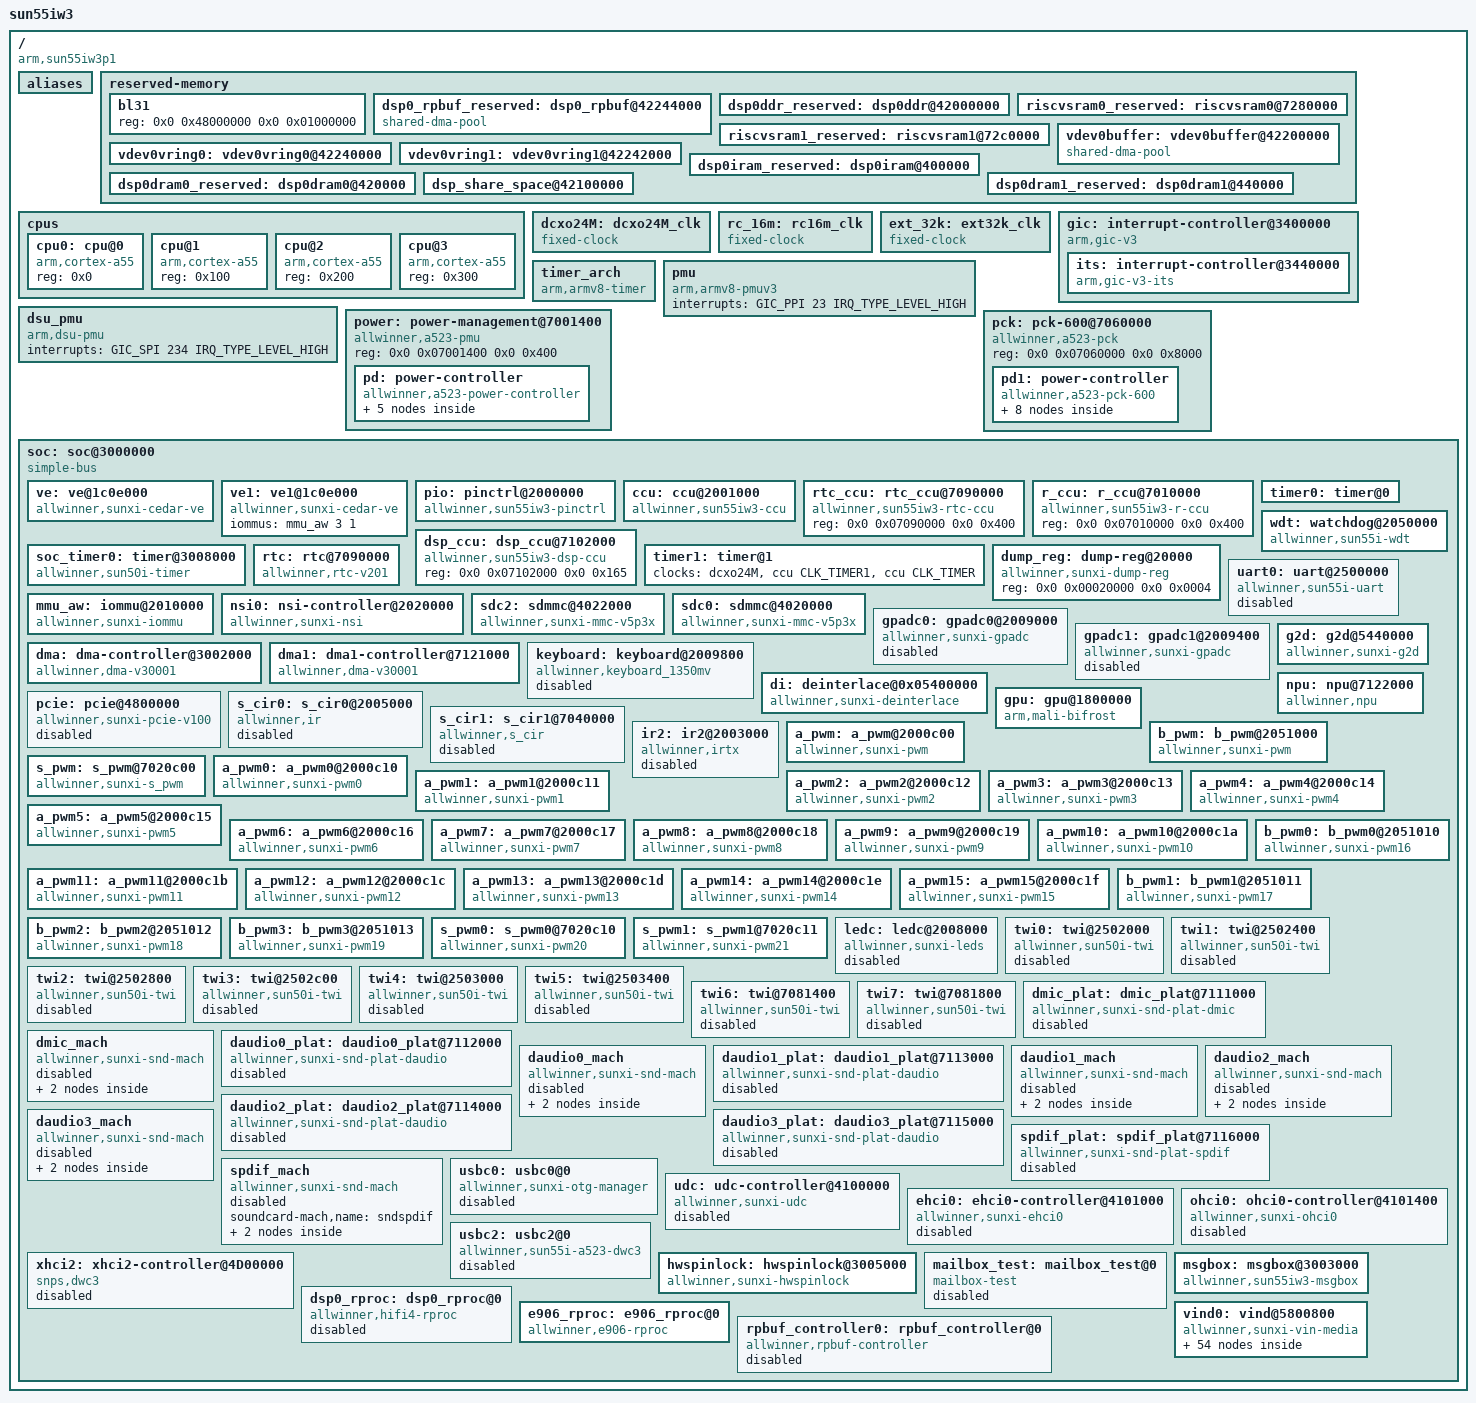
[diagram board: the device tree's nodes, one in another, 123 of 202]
// SPDX-License-Identifier: (GPL-2.0+ or MIT)
/*
 * Copyright (C) 2021 liujaun1@allwinnertech.com
 */

#include <dt-bindings/clock/sun55iw3-ccu.h>
#include <dt-bindings/clock/sun55iw3-rtc.h>
#include <dt-bindings/clock/sun55iw3-r-ccu.h>
#include <dt-bindings/clock/sun55iw3-dsp-ccu.h>
#include <dt-bindings/gpio/gpio.h>
#include <dt-bindings/interrupt-controller/arm-gic.h>
#include <dt-bindings/reset/sun55iw3-ccu.h>
#include <dt-bindings/reset/sun55iw3-r-ccu.h>
#include <dt-bindings/reset/sun55iw3-dsp-ccu.h>
#include <dt-bindings/power/a523-power.h>

/ {
	model = "sun55iw3";
	compatible = "arm,sun55iw3p1";
	interrupt-parent = <&gic>;
	#address-cells = <2>;
	#size-cells = <2>;
	aliases {
		global-timer0 = &soc_timer0;
		ir0 = &s_cir0;
		ir1 = &s_cir1;
		ir2 = &ir2;
		a-pwm = &a_pwm;
		b-pwm = &b_pwm;
		s-pwm = &s_pwm;
		a-pwm0 = &a_pwm0;
		a-pwm1 = &a_pwm1;
		a-pwm2 = &a_pwm2;
		a-pwm3 = &a_pwm3;
		a-pwm4 = &a_pwm4;
		a-pwm5 = &a_pwm5;
		a-pwm6 = &a_pwm6;
		a-pwm7 = &a_pwm7;
		a-pwm8 = &a_pwm8;
		a-pwm9 = &a_pwm9;
		a-pwm10 = &a_pwm10;
		a-pwm11 = &a_pwm11;
		a-pwm12 = &a_pwm12;
		a-pwm13 = &a_pwm13;
		a-pwm14 = &a_pwm14;
		a-pwm15 = &a_pwm15;
		b-pwm0 = &b_pwm0;
		b-pwm1 = &b_pwm1;
		b-pwm2 = &b_pwm2;
		b-pwm3 = &b_pwm3;
		s-pwm0 = &s_pwm0;
		s-pwm1 = &s_pwm1;
		pcie = &pcie;
		twi0 = &twi0;
		twi1 = &twi1;
		twi2 = &twi2;
		twi3 = &twi3;
		twi4 = &twi4;
		twi5 = &twi5;
		twi6 = &twi6;
		twi7 = &twi7;
		ve0 = &ve;
		ve1 = &ve1;
	};

	reserved-memory {
		#address-cells = <2>;
		#size-cells = <2>;
		ranges;

		bl31 {
			reg = <0x0 0x48000000 0x0 0x01000000>;
		};

		dsp0_rpbuf_reserved: dsp0_rpbuf@42244000 {
			compatible = "shared-dma-pool";
			no-map;
			reg = <0x0 0x42244000 0x0 0x2000>;
		};

		dsp0ddr_reserved: dsp0ddr@42000000 {
			reg = <0x0 0x42000000 0x0 0x00100000>;
			no-map;
		};

		riscvsram0_reserved: riscvsram0@7280000 {
			reg = <0x0 0x07280000 0x0 0x40000>;
			no-map;
		};

		riscvsram1_reserved: riscvsram1@72c0000 {
			reg = <0x0 0x072c0000 0x0 0x40000>;
			no-map;
		};

		/*
		 * The name should be "vdev%dbuffer".
		 * Its size should be not less than
		 *     RPMSG_BUF_SIZE * (num of buffers in a vring) * 2
		 *   = 512 * (num of buffers in a vring) * 2
		 */
		vdev0buffer: vdev0buffer@42200000 {
			compatible = "shared-dma-pool";
			reg = <0x0 0x42200000 0x0 0x40000>;
			no-map;
		};

		/*
		 * The name should be "vdev%dvring%d".
		 * The size of each should be not less than
		 *     PAGE_ALIGN(vring_size(num, align))
		 *   = PAGE_ALIGN(16 * num + 6 + 2 * num + (pads for align) + 6 + 8 * num)
		 *
		 * (Please refer to the vring layout in include/uapi/linux/virtio_ring.h)
		 */
		vdev0vring0: vdev0vring0@42240000 {
			reg = <0x0 0x42240000 0x0 0x2000>;
			no-map;
		};
		vdev0vring1: vdev0vring1@42242000 {
			reg = <0x0 0x42242000 0x0 0x2000>;
			no-map;
		};

		/*
		* dsp ram addr
		*/
		dsp0iram_reserved: dsp0iram@400000 {
			reg = <0x0 0x400000 0x0 0x10000>;
			no-map;
		};
		dsp0dram0_reserved: dsp0dram0@420000 {
			reg = <0x0 0x420000 0x0 0x8000>;
			no-map;
		};
		dsp0dram1_reserved: dsp0dram1@440000 {
			reg = <0x0 0x440000 0x0 0x8000>;
			no-map;
		};

		dsp_share_space@42100000 {
			no-map;
			reg = <0x0 0x42100000 0x0 0x10000>;
		};
	};

	cpus {
		#address-cells = <1>;
		#size-cells = <0>;

		cpu0: cpu@0 {
			device_type = "cpu";
			compatible = "arm,cortex-a55";
			reg = <0x0>;
		};

		cpu@1 {
			device_type = "cpu";
			compatible = "arm,cortex-a55";
			reg = <0x100>;
		};

		cpu@2 {
			device_type = "cpu";
			compatible = "arm,cortex-a55";
			reg = <0x200>;
		};

		cpu@3 {
			device_type = "cpu";
			compatible = "arm,cortex-a55";
			reg = <0x300>;
		};
	};

	dcxo24M: dcxo24M_clk {
		#clock-cells = <0>;
		compatible = "fixed-clock";
		clock-frequency = <24000000>;
		clock-output-names = "dcxo24M";
	};

	rc_16m: rc16m_clk {
		#clock-cells = <0>;
		compatible = "fixed-clock";
		clock-frequency = <16000000>;
		clock-accuracy = <300000000>;
		clock-output-names = "rc-16m";
	};

	ext_32k: ext32k_clk {
		#clock-cells = <0>;
		compatible = "fixed-clock";
		clock-frequency = <32768>;
		clock-output-names = "ext-32k";
	};

	gic: interrupt-controller@3400000 {
		compatible = "arm,gic-v3";
		#interrupt-cells = <3>;
		#address-cells = <0>;
		interrupt-controller;
		ranges;
		reg = <0x0 0x03400000 0 0x10000>, /* GIC Dist */
		      <0x0 0x03460000 0 0xFF004>; /* GIC Re */
		its: interrupt-controller@3440000 {
			compatible = "arm,gic-v3-its";
			reg = <0x0 0x03440000 0x0 0x20000>;
			msi-controller;
			#msi-cells = <1>;
		};
	};

	timer_arch {
		compatible = "arm,armv8-timer";
		interrupts = <GIC_PPI 13 (GIC_CPU_MASK_SIMPLE(4) | IRQ_TYPE_LEVEL_LOW)>,
			   <GIC_PPI 14 (GIC_CPU_MASK_SIMPLE(4) | IRQ_TYPE_LEVEL_LOW)>,
			   <GIC_PPI 11 (GIC_CPU_MASK_SIMPLE(4) | IRQ_TYPE_LEVEL_LOW)>,
			   <GIC_PPI 10 (GIC_CPU_MASK_SIMPLE(4) | IRQ_TYPE_LEVEL_LOW)>;
		clock-frequency = <24000000>;
		interrupt-parent = <&gic>;
		arm,no-tick-in-suspend;
	};

	pmu {
		compatible = "arm,armv8-pmuv3";
		interrupts = <GIC_PPI 23 IRQ_TYPE_LEVEL_HIGH>;
	};

	dsu_pmu {
		compatible = "arm,dsu-pmu";
		interrupts = <GIC_SPI 234 IRQ_TYPE_LEVEL_HIGH>;
	};

	power: power-management@7001400 {
		compatible = "allwinner,a523-pmu", "syscon", "simple-mfd";
		reg = <0x0 0x07001400 0x0 0x400>;

		pd: power-controller {
			compatible = "allwinner,a523-power-controller";
			clocks = <&r_ccu CLK_R_PPU1>;
			clock-names = "ppu";
			resets = <&r_ccu RST_R_PPU1>;
			reset-names = "ppu_rst";
			#power-domain-cells = <1>;
			#address-cells = <1>;
			#size-cells = <0>;

			pd_dsp@A523_PD_DSP {
				reg = <A523_PD_DSP>;
			};
			pd_npu@A523_PD_NPU {
				reg = <A523_PD_NPU>;
			};
			pd_audio@A523_PD_AUDIO {
				reg = <A523_PD_AUDIO>;
			};
			pd_sram@A523_PD_SRAM {
				reg = <A523_PD_SRAM>;
			};
			pd_riscv@A523_PD_RISCV {
				reg = <A523_PD_RISCV>;
			};
		};
	};

	pck: pck-600@7060000 {
		compatible = "allwinner,a523-pck", "syscon", "simple-mfd";
		reg = <0x0 0x07060000 0x0 0x8000>;

		pd1: power-controller {
			compatible = "allwinner,a523-pck-600";
			clocks = <&r_ccu CLK_R_PPU>;
			clock-names = "pck";
			resets = <&r_ccu RST_R_PPU>;
			reset-names = "pck_rst";
			#power-domain-cells = <1>;
			#address-cells = <1>;
			#size-cells = <0>;

			pd1_ve@A523_PCK_VE {
				reg = <A523_PCK_VE>;
			};
			pd1_gpu@A523_PCK_GPU {
				reg = <A523_PCK_GPU>;
			};
			pd1_vi@A523_PCK_VI {
				reg = <A523_PCK_VI>;
			};
			pd1_vo0@A523_PCK_VO0 {
				reg = <A523_PCK_VO0>;
			};
			pd1_vo1@A523_PCK_VO1 {
				reg = <A523_PCK_VO1>;
			};
			pd1_de@A523_PCK_DE {
				reg = <A523_PCK_DE>;
			};
			pd1_nand@A523_PCK_NAND {
				reg = <A523_PCK_NAND>;
			};
			pd1_pcie@A523_PCK_PCIE {
				reg = <A523_PCK_PCIE>;
			};
		};
	};

	soc: soc@3000000 {
		compatible = "simple-bus";
		#address-cells = <2>;
		#size-cells = <2>;
		ranges;

		ve: ve@1c0e000 {
			compatible = "allwinner,sunxi-cedar-ve";
			reg = <0x0 0x01c0e000 0x0 0x1000>,
				  <0x0 0x03000000 0x0 0x10>;
			interrupts = <GIC_SPI 120 IRQ_TYPE_LEVEL_HIGH>;
			clocks =<&ccu CLK_BUS_VE>, <&ccu CLK_VE>, <&ccu CLK_VE_MBUS_GATE>;
			clock-names = "bus_ve", "ve", "mbus_ve";
			resets = <&ccu RST_BUS_VE>;
			reset-names = "reset_ve";
			iommus = <&mmu_aw 3 1>;
		};

		ve1: ve1@1c0e000 {
			compatible = "allwinner,sunxi-cedar-ve";
			iommus = <&mmu_aw 3 1>;
		};

		pio: pinctrl@2000000 {
			compatible = "allwinner,sun55iw3-pinctrl";
			reg = <0x0 0x02000000 0x0 0x800>;
			interrupts = <GIC_SPI 67 IRQ_TYPE_LEVEL_HIGH>,
				     <GIC_SPI 69 IRQ_TYPE_LEVEL_HIGH>,
				     <GIC_SPI 71 IRQ_TYPE_LEVEL_HIGH>,
				     <GIC_SPI 73 IRQ_TYPE_LEVEL_HIGH>,
				     <GIC_SPI 75 IRQ_TYPE_LEVEL_HIGH>,
				     <GIC_SPI 77 IRQ_TYPE_LEVEL_HIGH>,
				     <GIC_SPI 79 IRQ_TYPE_LEVEL_HIGH>,
				     <GIC_SPI 81 IRQ_TYPE_LEVEL_HIGH>,
				     <GIC_SPI 83 IRQ_TYPE_LEVEL_HIGH>,
				     <GIC_SPI 85 IRQ_TYPE_LEVEL_HIGH>;
			clocks = <&ccu CLK_APB1>, <&dcxo24M>, <&rtc_ccu CLK_OSC32K>;
			clock-names = "apb", "hosc", "losc";
			gpio-controller;
			#gpio-cells = <3>;
			interrupt-controller;
			#interrupt-cells = <3>;

		};

		ccu: ccu@2001000 {
			compatible = "allwinner,sun55iw3-ccu";
			reg = <0x0 0x02001000 0x0 0x1000>;
			clocks = <&dcxo24M>, <&rtc_ccu CLK_OSC32K>, <&rc_16m>;
			clock-names = "hosc", "losc", "iosc";
			#clock-cells = <1>;
			#reset-cells = <1>;
		};

		rtc_ccu: rtc_ccu@7090000 {
			compatible = "allwinner,sun55iw3-rtc-ccu";
			reg = <0x0 0x07090000 0x0 0x400>;
			#clock-cells = <1>;
			#reset-cells = <1>;
		};

		r_ccu: r_ccu@7010000 {
			compatible = "allwinner,sun55iw3-r-ccu";
			reg = <0x0 0x07010000 0x0 0x400>;
			#clock-cells = <1>;
			#reset-cells = <1>;
		};

		dsp_ccu: dsp_ccu@7102000 {
			compatible = "allwinner,sun55iw3-dsp-ccu";
			reg = <0x0 0x07102000 0x0 0x165>;
			#clock-cells = <1>;
			#reset-cells = <1>;
		};

		soc_timer0: timer@3008000 {
			compatible = "allwinner,sun50i-timer";
			device_type = "soc_timer";
			reg = <0x0 0x03008000 0x0 0x400>;
			interrupt-parent = <&gic>;
			interrupts = <GIC_SPI 55 IRQ_TYPE_LEVEL_HIGH>;
			sunxi-timers = <&timer0>, <&timer1>;
		};

		timer0: timer@0 {
			clocks = <&dcxo24M>, <&ccu CLK_TIMER0>, <&ccu CLK_TIMER>;
			clock-names = "parent", "mod", "bus";
			resets = <&ccu RST_BUS_TIME>;
		};

		timer1: timer@1 {
			clocks = <&dcxo24M>, <&ccu CLK_TIMER1>, <&ccu CLK_TIMER>;
			clock-names = "parent", "mod", "bus";
		};

		dump_reg: dump-reg@20000 {
			compatible = "allwinner,sunxi-dump-reg";
			reg = <0x0 0x00020000 0x0 0x0004>;
		};

		wdt: watchdog@2050000 {
			compatible = "allwinner,sun55i-wdt";
			reg = <0x0 0x02050000 0x0 0x20>;  /* In Timers Spec */
			interrupts = <GIC_SPI 63 IRQ_TYPE_LEVEL_HIGH>;  /* In GIC Spec */
		};

		rtc: rtc@7090000 {
			compatible = "allwinner,rtc-v201";
			device_type = "rtc";
			wakeup-source;
			reg = <0x0 0x07090000 0x0 0x320>;
			interrupts = <GIC_SPI 157 IRQ_TYPE_LEVEL_HIGH>;
			clocks = <&r_ccu CLK_BUS_R_RTC>, <&rtc_ccu CLK_RTC_1K>, <&rtc_ccu CLK_RTC_SPI>;
			clock-names = "r-ahb-rtc", "rtc-1k", "rtc-spi";
			resets = <&r_ccu RST_R_RTC>;
			gpr_cur_pos = <6>;
		};

		uart0: uart@2500000 {
			compatible = "allwinner,sun55i-uart";
			reg = <0x0 0x02500000 0x0 0x400>;
			interrupts = <GIC_SPI 2 IRQ_TYPE_LEVEL_HIGH>;
			clocks = <&ccu CLK_BUS_UART0>;
			resets = <&ccu RST_BUS_UART0>;
			uart0_port = <0>;
			uart0_type = <4>;
			status = "disabled";
		};

		mmu_aw: iommu@2010000 {
			compatible = "allwinner,sunxi-iommu";
			reg = <0x0 0x02010000 0x0 0x1000>;
			interrupts = <GIC_SPI 65 IRQ_TYPE_LEVEL_HIGH>;
			interrupt-names = "iommu-irq";
			clocks = <&ccu CLK_IOMMU>;
			clock-names = "iommu";
			#iommu-cells = <2>;
		};

		nsi0:nsi-controller@2020000 {
			compatible = "allwinner,sunxi-nsi";
			interrupts = <GIC_SPI 43 IRQ_TYPE_LEVEL_HIGH>;
			reg = <0x0 0x02020000 0x0 0x10000>,
			      <0x0 0x02071000 0x0 0x400>;
			clocks = <&ccu CLK_PLL_PERI1_400M>, <&ccu CLK_MBUS>, <&ccu CLK_PLL_DDR>;
			clock-names = "pll", "bus", "sdram";
			resets = <&ccu RST_MBUS>;
			clock-frequency = <400000000>;
		};

		sdc2: sdmmc@4022000 {
			compatible = "allwinner,sunxi-mmc-v5p3x";
			device_type = "sdc2";
			reg = <0x0 0x04022000 0x0 0x1000>;
			interrupts = <GIC_SPI 42 IRQ_TYPE_LEVEL_HIGH>;
			clocks = <&dcxo24M>,
			<&ccu CLK_SMHC2>,
			<&ccu CLK_BUS_SMHC2>;
			clock-names = "osc24m","mmc","ahb";
			resets = <&ccu RST_BUS_SMHC2>;
			reset-names = "rst";
			bus-width = <8>;
			req-page-count = <2>;
			cap-mmc-highspeed;
			cap-cmd23;
			mmc-cache-ctrl;
			non-removable;
			/*max-frequency = <200000000>;*/
			max-frequency = <50000000>;
			cap-erase;
			mmc-high-capacity-erase-size;
			no-sdio;
			no-sd;
			/*-- speed mode --*/
			/*sm0: DS26_SDR12*/
			/*sm1: HSSDR52_SDR25*/
			/*sm2: HSDDR52_DDR50*/
			/*sm3: HS200_SDR104*/
			/*sm4: HS400*/
			/*-- frequency point --*/
			/*f0: CLK_400K*/
			/*f1: CLK_25M*/
			/*f2: CLK_50M*/
			/*f3: CLK_100M*/
			/*f4: CLK_150M*/
			/*f5: CLK_200M*/

			sdc_tm4_sm0_freq0 = <0>;
			sdc_tm4_sm0_freq1 = <0>;
			sdc_tm4_sm1_freq0 = <0x00000000>;
			sdc_tm4_sm1_freq1 = <0>;
			sdc_tm4_sm2_freq0 = <0x00000000>;
			sdc_tm4_sm2_freq1 = <0>;
			sdc_tm4_sm3_freq0 = <0x05000000>;
			sdc_tm4_sm3_freq1 = <0x00000005>;
			sdc_tm4_sm4_freq0 = <0x00050000>;
			sdc_tm4_sm4_freq1 = <0x00000004>;
			sdc_tm4_sm4_freq0_cmd = <0>;
			sdc_tm4_sm4_freq1_cmd = <0>;

			/*vmmc-supply = <&reg_3p3v>;*/
			/*vqmc-supply = <&reg_3p3v>;*/
			/*vdmc-supply = <&reg_3p3v>;*/
			/*vmmc = "vcc-card";*/
			/*vqmc = "";*/
			/*vdmc = "";*/
			/*sunxi-power-save-mode;*/
		};

		sdc0: sdmmc@4020000 {
			compatible = "allwinner,sunxi-mmc-v5p3x";
			device_type = "sdc0";
			reg = <0x0 0x04020000 0x0 0x1000>;
			interrupts = <GIC_SPI 40 IRQ_TYPE_LEVEL_HIGH>;
			clocks = <&dcxo24M>,
				<&ccu CLK_SMHC0>,
				<&ccu CLK_BUS_SMHC0>;
			clock-names = "osc24m","mmc","ahb";
			resets = <&ccu RST_BUS_SMHC0>;
			reset-names = "rst";
		};

		gpadc0: gpadc0@2009000 {
			compatible = "allwinner,sunxi-gpadc";
			reg = <0x0 0x02009000 0x0 0x200>;
			interrupts = <GIC_SPI 61 IRQ_TYPE_LEVEL_HIGH>;
			clocks = <&ccu CLK_BUS_GPADC0>;
			clock-names = "bus";
			resets = <&ccu RST_BUS_GPADC0>;
			status = "disabled";
		};

		gpadc1: gpadc1@2009400 {
			compatible = "allwinner,sunxi-gpadc";
			reg = <0x0 0x02009400 0x0 0x200>;
			interrupts = <GIC_SPI 64 IRQ_TYPE_LEVEL_HIGH>;
			clocks = <&ccu CLK_BUS_GPADC1>;
			clock-names = "bus";
			resets = <&ccu RST_BUS_GPADC1>;
			status = "disabled";
		};

		dma:dma-controller@3002000 {
			compatible = "allwinner,dma-v30001";
			reg = <0x0 0x03002000 0x0 0x1000>;
			interrupts = <GIC_SPI 50 IRQ_TYPE_LEVEL_HIGH>;
			clocks = <&ccu CLK_DMA>, <&ccu CLK_DMA_MBUS_GATE>;
			clock-names = "bus", "mbus";
			dma-channels = <16>;
			dma-requests = <54>;
			resets = <&ccu RST_BUS_DMA>;
			#dma-cells = <1>;
		};

		dma1:dma1-controller@7121000 {
			compatible = "allwinner,dma-v30001";
			reg = <0x0 0x07121000 0x0 0x1000>;
			interrupts = <GIC_SPI 197 IRQ_TYPE_LEVEL_HIGH>;
			clocks = <&dsp_ccu CLK_BUS_DSP_DMA>, <&dsp_ccu CLK_BUS_DSP_MBUS>;
			clock-names = "bus", "mbus";
			dma-channels = <16>;
			dma-requests = <54>;
			resets = <&dsp_ccu RST_BUS_DSP_DMA>;
			#dma-cells = <1>;
		};

		keyboard: keyboard@2009800 {
			compatible = "allwinner,keyboard_1350mv";
			reg = <0x0 0x02009800 0x0 0x100>;
			interrupts = <GIC_SPI 66 IRQ_TYPE_NONE>;
			clocks = <&ccu CLK_LRADC>;
			resets = <&ccu RST_BUS_LRADC>;
			status = "disabled";
			key_cnt = <5>;
			key0 = <212 115>;
			key1 = <409 114>;
			key2 = <473 139>;
			key3 = <525 28>;
			key4 = <527 172>;
		};

		di:deinterlace@0x05400000{
			#address-cells = <1>;
			#size-cells = <0>;
			compatible = "allwinner,sunxi-deinterlace";
			reg = <0x0 0x05400000 0x0 0x040000>;
			interrupts = <GIC_SPI 88 IRQ_TYPE_LEVEL_HIGH>;
			iommus = <&mmu_aw 6 1>;
			status = "okay";

			clocks = <&ccu CLK_DI>,
				 <&ccu CLK_BUS_DI>,
				 <&ccu CLK_PLL_PERI0_2X>;
			clock-names = "clk_di",
				      "clk_bus_di",
				      "pll_periph";
			resets = <&ccu RST_BUS_DI>;
			reset-names = "rst_bus_di";

			assigned-clocks = <&ccu CLK_DI>;
			assigned-clock-parents = <&ccu CLK_PLL_PERI0_2X>;
			assigned-clock-rates = <300000000>;
		};

		g2d: g2d@5440000 {
			compatible = "allwinner,sunxi-g2d";
			reg = <0x0 0x05440000 0x0 0x3ffff>;
			interrupts = <GIC_SPI 143 IRQ_TYPE_LEVEL_HIGH>;
			clocks = <&ccu CLK_BUS_G2D>, <&ccu CLK_G2D>;
			clock-names = "bus", "g2d";
			resets = <&ccu RST_BUS_G2D>;
			assigned-clocks = <&ccu CLK_G2D>;
			assigned-clock-parents = <&ccu CLK_PLL_VIDEO1_4X>;
			/*assigned-clock-rates = <300000000>;*/
			iommus = <&mmu_aw 4 1>;
		};

		npu: npu@7122000 {
			compatible = "allwinner,npu";
			reg = <0x0 0x07122000 0x0 0x1000>;
			device_type = "npu";
			dev_name = "npu";
			interrupts = <GIC_SPI 199 IRQ_TYPE_LEVEL_HIGH>;
			clocks = <&ccu CLK_NPU>, <&ccu CLK_PLL_NPU_2X>;
			clock-names = "clk_npu", "clk_parent";
			clock-frequency = <600000000>;
			resets = <&dsp_ccu RST_BUS_DSP_NPU>;
			interrupt-names = "npu";
			etatus = "okay";
/*
			power-domains = <&pd A523_PD_NPU>;
*/
			};

		gpu: gpu@1800000 {
			device_type = "gpu";
			compatible = "arm,mali-bifrost";
			reg = <0x0 0x01800000 0x0 0x40000>;
			interrupts = <GIC_SPI 117 IRQ_TYPE_LEVEL_HIGH>,
				     <GIC_SPI 118 IRQ_TYPE_LEVEL_HIGH>,
				     <GIC_SPI 119 IRQ_TYPE_LEVEL_HIGH>;
			interrupt-names = "JOB", "MMU", "GPU";
			clocks = <&ccu CLK_PLL_GPU>, <&ccu CLK_GPU>;
			clock-names = "clk_parent", "clk_mali";

			resets = <&ccu RST_BUS_GPU>;
			reset-names = "rst_bus_gpu";
			power-domains = <&pd1 A523_PCK_GPU>;
			/*#cooling-cells = <2>;
			ipa_dvfs:ipa_dvfs {
				compatible = "arm,mali-simple-power-model";
				static-coefficient = <17000>;
				dynamic-coefficient = <750>;
				ts = <254682 9576 0xffffff98 4>;
				thermal-zone = "gpu-thermal-zone";
				ss-coefficient = <36>;
				ff-coefficient = <291>;
			};*/
		};

		pcie: pcie@4800000 {
			#address-cells = <3>;
			#size-cells = <2>;
			compatible = "allwinner,sunxi-pcie-v100";
			bus-range = <0x0 0xff>;
			reg = <0 0x04800000 0 0x480000>,
			      <0 0x04f00000 0 0x88>,
			      <0 0x02001a84 0 0x30>;
			reg-names = "dbi", "pcie-phy", "clk_add";
			device_type = "pci";
			ranges = <0x00000800 0 0x20000000 0x0 0x20000000 0 0x01000000
				  0x81000000 0 0x21000000 0x0 0x21000000 0 0x01000000
				  0x82000000 0 0x22000000 0x0 0x22000000 0 0x07000000>;
			num-lanes = <1>;
			interrupts = <GIC_SPI 107 IRQ_TYPE_LEVEL_HIGH>,
				     <GIC_SPI 106 IRQ_TYPE_LEVEL_HIGH>,
				     <GIC_SPI 98  IRQ_TYPE_LEVEL_HIGH>,
				     <GIC_SPI 99  IRQ_TYPE_LEVEL_HIGH>,
				     <GIC_SPI 100 IRQ_TYPE_LEVEL_HIGH>,
				     <GIC_SPI 101 IRQ_TYPE_LEVEL_HIGH>,
				     <GIC_SPI 102 IRQ_TYPE_LEVEL_HIGH>,
				     <GIC_SPI 103 IRQ_TYPE_LEVEL_HIGH>,
				     <GIC_SPI 104 IRQ_TYPE_LEVEL_HIGH>,
				     <GIC_SPI 105 IRQ_TYPE_LEVEL_HIGH>;
			interrupt-names = "msi", "sii", "edma-w0", "edma-w1", "edma-w2", "edma-w3",
					  "edma-r0", "edma-r1", "edma-r2", "edma-r3";
			#interrupt-cells = <1>;
			num-edma = <4>;
			pcie_speed_gen = <1>;
			num-ib-windows = <8>;
			num-ob-windows = <8>;
			clocks = <&ccu CLK_USB3_REF >, <&ccu CLK_PLL_PERI0_200M>, <&ccu CLK_PCIE_AUX>;
			clock-names = "pclk_ref", "pclk_per", "pclk_aux";
			resets = <&ccu RST_BUS_PCIE_USB3>;
			reset-names = "pclk_rst";
			busno = <0>;
			/* msi-map = <0x0 &its 0x0 0x1000>; Do not use ITS: Need to modify the ITS driver */
			status = "disabled";
		};

		s_cir0: s_cir0@2005000 {
			compatible = "allwinner,ir";
			reg = <0x0 0x02005000 0x0 0x400>;
			interrupts = <GIC_SPI 27 IRQ_TYPE_LEVEL_HIGH>;
			clocks = <&ccu CLK_BUS_IRRX>, <&dcxo24M>, <&ccu CLK_IRRX>;
			clock-names = "bus", "pclk", "mclk";
			resets = <&ccu RST_BUS_IRRX>;
			status = "disabled";
		};

		s_cir1: s_cir1@7040000 {
			compatible = "allwinner,s_cir";
			reg = <0x0 0x07040000 0x0 0x400>;
			interrupts = <GIC_SPI 167 IRQ_TYPE_LEVEL_HIGH>;
			clocks = <&r_ccu CLK_BUS_R_IRRX>, <&dcxo24M>, <&r_ccu CLK_R_IRRX>;
			clock-names = "bus", "pclk", "mclk";
			resets = <&r_ccu RST_R_IRRX>;
			status = "disabled";
		};

		ir2: ir2@2003000 {
			compatible = "allwinner,irtx";
			reg = <0x0 0x02003000 0x0 0x400>;
			interrupts = <GIC_SPI 26 IRQ_TYPE_LEVEL_HIGH>;
			clocks = <&ccu CLK_BUS_IRTX>, <&dcxo24M>, <&ccu CLK_IRTX>;
			clock-names = "bus", "pclk", "mclk";
			resets = <&ccu RST_BUS_IRTX>;
			status = "disabled";
		};

		a_pwm: a_pwm@2000c00 {
			#pwm-cells = <0x3>;
			compatible = "allwinner,sunxi-pwm";
			reg = <0x0 0x02000c00 0x0 0x3ff>;
			clocks = <&ccu CLK_PWM>;
			resets = <&ccu RST_BUS_PWM>;
			pwm-number = <16>;
			pwm-base = <0x0>;
			sunxi-pwms = <&a_pwm0>, <&a_pwm1>, <&a_pwm2>, <&a_pwm3>, <&a_pwm4>,
				<&a_pwm5>, <&a_pwm6>, <&a_pwm7>, <&a_pwm8>, <&a_pwm9>,
				<&a_pwm10>, <&a_pwm11>, <&a_pwm12>, <&a_pwm13>,
				<&a_pwm14>, <&a_pwm15>;
		};

		b_pwm: b_pwm@2051000 {
			#pwm-cells = <0x3>;
			compatible = "allwinner,sunxi-pwm";
			reg = <0x0 0x02051000 0x0 0x3ff>;
			clocks = <&ccu CLK_PWM1>;
			resets = <&ccu RST_BUS_PWM1>;
			pwm-number = <4>;
			pwm-base = <0x10>;
			sunxi-pwms = <&b_pwm0>, <&b_pwm1>, <&b_pwm2>, <&b_pwm3>;
		};

		s_pwm: s_pwm@7020c00 {
			#pwm-cells = <0x3>;
			compatible = "allwinner,sunxi-s_pwm";
			reg = <0x0 0x07020c00 0x0 0x3ff>;
			clocks = <&r_ccu CLK_R_PWM>;
			resets = <&r_ccu RST_R_PWM>;
			pwm-number = <2>;
			pwm-base = <0x20>;
			sunxi-pwms = <&s_pwm0>, <&s_pwm1>;
		};

		a_pwm0: a_pwm0@2000c10 {
			compatible = "allwinner,sunxi-pwm0";
			pinctrl-names = "active", "sleep";
			reg = <0x0 0x02000c10 0x0 0x4>;
			reg_base = <0x02000c00>;
		};

		a_pwm1: a_pwm1@2000c11 {
			compatible = "allwinner,sunxi-pwm1";
			pinctrl-names = "active", "sleep";
			reg = <0x0 0x02000c11 0x0 0x4>;
			reg_base = <0x02000c00>;
		};

		a_pwm2: a_pwm2@2000c12 {
			compatible = "allwinner,sunxi-pwm2";
			pinctrl-names = "active", "sleep";
			reg = <0x0 0x02000c12 0x0 0x4>;
			reg_base = <0x02000c00>;
		};

		a_pwm3: a_pwm3@2000c13 {
			compatible = "allwinner,sunxi-pwm3";
			pinctrl-names = "active", "sleep";
			reg = <0x0 0x02000c13 0x0 0x4>;
			reg_base = <0x02000c00>;
		};

		a_pwm4: a_pwm4@2000c14 {
			compatible = "allwinner,sunxi-pwm4";
			pinctrl-names = "active", "sleep";
			reg = <0x0 0x02000c14 0x0 0x4>;
			reg_base = <0x02000c00>;
		};

		a_pwm5: a_pwm5@2000c15 {
			compatible = "allwinner,sunxi-pwm5";
			pinctrl-names = "active", "sleep";
			reg = <0x0 0x02000c15 0x0 0x4>;
			reg_base = <0x02000c00>;
		};

		a_pwm6: a_pwm6@2000c16 {
			compatible = "allwinner,sunxi-pwm6";
			pinctrl-names = "active", "sleep";
			reg = <0x0 0x02000c16 0x0 0x4>;
			reg_base = <0x02000c00>;
		};

		a_pwm7: a_pwm7@2000c17 {
			compatible = "allwinner,sunxi-pwm7";
			pinctrl-names = "active", "sleep";
			reg = <0x0 0x02000c17 0x0 0x4>;
			reg_base = <0x02000c00>;
		};

		a_pwm8: a_pwm8@2000c18 {
			compatible = "allwinner,sunxi-pwm8";
			pinctrl-names = "active", "sleep";
			reg = <0x0 0x02000c18 0x0 0x4>;
			reg_base = <0x02000c00>;
		};

		a_pwm9: a_pwm9@2000c19 {
			compatible = "allwinner,sunxi-pwm9";
			pinctrl-names = "active", "sleep";
			reg = <0x0 0x02000c19 0x0 0x4>;
			reg_base = <0x02000c00>;
		};

		a_pwm10: a_pwm10@2000c1a {
			compatible = "allwinner,sunxi-pwm10";
			pinctrl-names = "active", "sleep";
			reg = <0x0 0x02000c1a 0x0 0x4>;
			reg_base = <0x02000c00>;
		};

		a_pwm11: a_pwm11@2000c1b {
			compatible = "allwinner,sunxi-pwm11";
			pinctrl-names = "active", "sleep";
			reg = <0x0 0x02000c1b 0x0 0x4>;
			reg_base = <0x02000c00>;
		};

		a_pwm12: a_pwm12@2000c1c {
			compatible = "allwinner,sunxi-pwm12";
			pinctrl-names = "active", "sleep";
			reg = <0x0 0x02000c1c 0x0 0x4>;
			reg_base = <0x02000c00>;
		};

		a_pwm13: a_pwm13@2000c1d {
			compatible = "allwinner,sunxi-pwm13";
			pinctrl-names = "active", "sleep";
			reg = <0x0 0x02000c1d 0x0 0x4>;
			reg_base = <0x02000c00>;
		};

		a_pwm14: a_pwm14@2000c1e {
			compatible = "allwinner,sunxi-pwm14";
			pinctrl-names = "active", "sleep";
			reg = <0x0 0x02000c1e 0x0 0x4>;
			reg_base = <0x02000c00>;
		};

		a_pwm15: a_pwm15@2000c1f {
			compatible = "allwinner,sunxi-pwm15";
			pinctrl-names = "active", "sleep";
			reg = <0x0 0x02000c1f 0x0 0x4>;
			reg_base = <0x02000c00>;
		};

		b_pwm0: b_pwm0@2051010 {
			compatible = "allwinner,sunxi-pwm16";
			pinctrl-names = "active", "sleep";
			reg = <0x0 0x02051010 0x0 0x4>;
			reg_base = <0x02051000>;
		};

		b_pwm1: b_pwm1@2051011 {
			compatible = "allwinner,sunxi-pwm17";
			pinctrl-names = "active", "sleep";
			reg = <0x0 0x02051011 0x0 0x4>;
			reg_base = <0x02051000>;
		};

		b_pwm2: b_pwm2@2051012 {
			compatible = "allwinner,sunxi-pwm18";
			pinctrl-names = "active", "sleep";
			reg = <0x0 0x02051012 0x0 0x4>;
			reg_base = <0x02051000>;
		};

		b_pwm3: b_pwm3@2051013 {
			compatible = "allwinner,sunxi-pwm19";
			pinctrl-names = "active", "sleep";
			reg = <0x0 0x02051013 0x0 0x4>;
			reg_base = <0x02051000>;
		};

		s_pwm0: s_pwm0@7020c10 {
			compatible = "allwinner,sunxi-pwm20";
			pinctrl-names = "active", "sleep";
			reg = <0x0 0x07020c10 0x0 0x4>;
			reg_base = <0x07020c00>;
		};

		s_pwm1: s_pwm1@7020c11 {
			compatible = "allwinner,sunxi-pwm21";
			pinctrl-names = "active", "sleep";
			reg = <0x0 0x07020c11 0x0 0x4>;
			reg_base = <0x07020c00>;
		};

		ledc: ledc@2008000 {
			#address-cells = <1>;
			#size-cells = <0>;
			compatible = "allwinner,sunxi-leds";
			reg = <0x0 0x02008000 0x0 0x400>;
			interrupts = <GIC_SPI 28 IRQ_TYPE_LEVEL_HIGH>;
			clocks = <&ccu CLK_LEDC>, <&ccu CLK_BUS_LEDC>;
			clock-names = "clk_ledc", "clk_cpuapb";
			resets = <&ccu RST_BUS_LEDC>;
			reset-names = "ledc_reset";
			dmas = <&dma 42>, <&dma 42>;
			dma-names = "rx", "tx";
			status = "disabled";
		};

		twi0: twi@2502000 {
			#address-cells = <1>;
			#size-cells = <0>;
			compatible = "allwinner,sun50i-twi";
			device_type = "twi0";
			reg = <0x0 0x02502000 0x0 0x400>;
			interrupts = <GIC_SPI 10 IRQ_TYPE_LEVEL_HIGH>;
			clocks = <&ccu CLK_TWI0>;
			clock-names = "bus";
			resets = <&ccu RST_BUS_TWI0>;
			dmas = <&dma 43>, <&dma 43>;
			dma-names = "tx", "rx";
			status = "disabled";
		};

		twi1: twi@2502400 {
			#address-cells = <1>;
			#size-cells = <0>;
			compatible = "allwinner,sun50i-twi";
			device_type = "twi1";
			reg = <0x0 0x02502400 0x0 0x400>;
			interrupts = <GIC_SPI 11 IRQ_TYPE_LEVEL_HIGH>;
			clocks = <&ccu CLK_TWI1>;
			clock-names = "bus";
			resets = <&ccu RST_BUS_TWI1>;
			dmas = <&dma 44>, <&dma 44>;
			dma-names = "tx", "rx";
			status = "disabled";
		};

		twi2: twi@2502800 {
			#address-cells = <1>;
			#size-cells = <0>;
			compatible = "allwinner,sun50i-twi";
			device_type = "twi2";
			reg = <0x0 0x02502800 0x0 0x400>;
			interrupts = <GIC_SPI 12 IRQ_TYPE_LEVEL_HIGH>;
			clocks = <&ccu CLK_TWI2>;
			clock-names = "bus";
			resets = <&ccu RST_BUS_TWI2>;
			dmas = <&dma 45>, <&dma 45>;
			dma-names = "tx", "rx";
			status = "disabled";
		};

		twi3: twi@2502c00 {
			#address-cells = <1>;
			#size-cells = <0>;
			compatible = "allwinner,sun50i-twi";
			device_type = "twi3";
			reg = <0x0 0x02502c00 0x0 0x400>;
			interrupts = <GIC_SPI 13 IRQ_TYPE_LEVEL_HIGH>;
			clocks = <&ccu CLK_TWI3>;
			clock-names = "bus";
			resets = <&ccu RST_BUS_TWI3>;
			dmas = <&dma 46>, <&dma 46>;
			dma-names = "tx", "rx";
			status = "disabled";
		};

		twi4: twi@2503000 {
			#address-cells = <1>;
			#size-cells = <0>;
			compatible = "allwinner,sun50i-twi";
			device_type = "twi4";
			reg = <0x0 0x02503000 0x0 0x400>;
			interrupts = <GIC_SPI 14 IRQ_TYPE_LEVEL_HIGH>;
			clocks = <&ccu CLK_TWI4>;
			clock-names = "bus";
			resets = <&ccu RST_BUS_TWI4>;
			dmas = <&dma 47>, <&dma 47>;
			dma-names = "tx", "rx";
			status = "disabled";
		};

		twi5: twi@2503400{
			#address-cells = <1>;
			#size-cells = <0>;
			compatible = "allwinner,sun50i-twi";
			device_type = "twi5";
			reg = <0x0 0x02503400 0x0 0x400>;
			interrupts = <GIC_SPI 15 IRQ_TYPE_LEVEL_HIGH>;
			clocks = <&ccu CLK_TWI5>;
			clock-names = "bus";
			resets = <&ccu RST_BUS_TWI5>;
			dmas = <&dma 48>, <&dma 48>;
			dma-names = "tx", "rx";
			status = "disabled";
		};

		twi6: twi@7081400 {
			#address-cells = <1>;
			#size-cells = <0>;
			compatible = "allwinner,sun50i-twi";
			device_type = "twi6";
			reg = <0x0 0x07081400 0x0 0x400>;
			interrupts = <GIC_SPI 164 IRQ_TYPE_LEVEL_HIGH>;
			clocks = <&r_ccu CLK_BUS_R_TWI0>;
			clock-names = "bus";
			resets = <&r_ccu RST_R_TWI0>;
			dmas = <&dma 49>, <&dma 49>;
			dma-names = "tx", "rx";
			status = "disabled";
		};

		twi7: twi@7081800 {
			#address-cells = <1>;
			#size-cells = <0>;
			compatible = "allwinner,sun50i-twi";
			device_type = "twi7";
			reg = <0x0 0x07081800 0x0 0x400>;
			interrupts = <GIC_SPI 165 IRQ_TYPE_LEVEL_HIGH>;
			clocks = <&r_ccu CLK_BUS_R_TWI1>;
			clock-names = "bus";
			resets = <&r_ccu RST_R_TWI1>;
			dmas = <&dma 50>, <&dma 50>;
			dma-names = "tx", "rx";
			status = "disabled";
		};

		/* audio dirver module -> dmic */
		dmic_plat:dmic_plat@7111000 {
			#sound-dai-cells = <0>;
			compatible	= "allwinner,sunxi-snd-plat-dmic";
			reg		= <0x0 0x07111000 0x0 0x50>;
			resets		= <&dsp_ccu RST_BUS_DSP_DMIC>;
			clocks		= <&dsp_ccu CLK_BUS_DSP_DMIC>,
					  <&dsp_ccu CLK_PLL_DSP_AUDIO1_DIV2>,
					  <&dsp_ccu CLK_PLL_DSP_AUDIO1_DIV5>,
					  <&ccu CLK_PLL_AUDIO0_4X>,
					  <&dsp_ccu CLK_DSP_DMIC>;
			clock-names	= "clk_bus_dmic",
					  "clk_pll_audio1_d2",
					  "clk_pll_audio1_d5",
					  "clk_pll_audio0_4x",
					  "clk_dmic";
			dmas		= <&dma1 8>;
			dma-names	= "rx";
			capture-cma	= <128>;
			rx-fifo-size	= <128>;
			status = "disabled";
		};

		dmic_mach:dmic_mach{
			compatible = "allwinner,sunxi-snd-mach";
			soundcard-mach,name		= "snddmic";
			soundcard-mach,capture-only;
			status = "disabled";
			soundcard-mach,cpu {
				sound-dai = <&dmic_plat>;
			};
			soundcard-mach,codec {
			};
		};

		/* audio dirver module -> I2S/PCM */
		daudio0_plat:daudio0_plat@7112000 {
			#sound-dai-cells = <0>;
			compatible = "allwinner,sunxi-snd-plat-daudio";
			reg		= <0x0 0x07112000 0x0 0xA0>;
			resets		= <&dsp_ccu RST_BUS_DSP_I2S0>;
			clocks		= <&dsp_ccu CLK_BUS_DSP_I2S0>,
					  <&dsp_ccu CLK_PLL_DSP_AUDIO1_DIV2>,
					  <&dsp_ccu CLK_PLL_DSP_AUDIO1_DIV5>,
					  <&ccu CLK_PLL_AUDIO0_4X>,
					  <&dsp_ccu CLK_DSP_I2S0>;
			clock-names	= "clk_bus_i2s",
					  "clk_pll_audio1_d2",
					  "clk_pll_audio1_d5",
					  "clk_pll_audio0_4x",
					  "clk_i2s";
			dmas		= <&dma1 3>, <&dma1 3>;
			dma-names	= "tx", "rx";
			playback-cma	= <128>;
			capture-cma	= <128>;
			tx-fifo-size	= <128>;
			rx-fifo-size	= <128>;
			status = "disabled";
		};

		daudio0_mach:daudio0_mach{
			compatible = "allwinner,sunxi-snd-mach";
			soundcard-mach,name		= "snddaudio0";
			soundcard-mach,format		= "i2s";
			soundcard-mach,slot-num		= <2>;
			soundcard-mach,slot-width	= <32>;
			status = "disabled";
			soundcard-mach,cpu {
				sound-dai = <&daudio0_plat>;
			};
			soundcard-mach,codec {
			};
		};

		daudio1_plat:daudio1_plat@7113000 {
			#sound-dai-cells = <0>;
			compatible = "allwinner,sunxi-snd-plat-daudio";
			reg		= <0x0 0x07113000 0x0 0xA0>;
			resets		= <&dsp_ccu RST_BUS_DSP_I2S1>;
			clocks		= <&dsp_ccu CLK_BUS_DSP_I2S1>,
					  <&dsp_ccu CLK_PLL_DSP_AUDIO1_DIV2>,
					  <&dsp_ccu CLK_PLL_DSP_AUDIO1_DIV5>,
					  <&ccu CLK_PLL_AUDIO0_4X>,
					  <&dsp_ccu CLK_DSP_I2S1>;
			clock-names	= "clk_bus_i2s",
					  "clk_pll_audio1_d2",
					  "clk_pll_audio1_d5",
					  "clk_pll_audio0_4x",
					  "clk_i2s";
			dmas		= <&dma1 4>, <&dma1 4>;
			dma-names	= "tx", "rx";
			playback-cma	= <128>;
			capture-cma	= <128>;
			tx-fifo-size	= <128>;
			rx-fifo-size	= <128>;
			status = "disabled";
		};

		daudio1_mach:daudio1_mach{
			compatible = "allwinner,sunxi-snd-mach";
			soundcard-mach,name		= "snddaudio1";
			soundcard-mach,format		= "i2s";
			soundcard-mach,slot-num		= <2>;
			soundcard-mach,slot-width	= <32>;
			status = "disabled";
			soundcard-mach,cpu {
				sound-dai = <&daudio1_plat>;
			};
			soundcard-mach,codec {
			};
		};

		daudio2_plat:daudio2_plat@7114000 {
			#sound-dai-cells = <0>;
			compatible = "allwinner,sunxi-snd-plat-daudio";
			reg		= <0x0 0x07114000 0x0 0xA0>;
			resets		= <&dsp_ccu RST_BUS_DSP_I2S2>;
			clocks		= <&dsp_ccu CLK_BUS_DSP_I2S2>,
					  <&dsp_ccu CLK_PLL_DSP_AUDIO1_DIV2>,
					  <&dsp_ccu CLK_PLL_DSP_AUDIO1_DIV5>,
					  <&ccu CLK_PLL_AUDIO0_4X>,
					  <&dsp_ccu CLK_DSP_I2S2>;
			clock-names	= "clk_bus_i2s",
					  "clk_pll_audio1_d2",
					  "clk_pll_audio1_d5",
					  "clk_pll_audio0_4x",
					  "clk_i2s";
			dmas		= <&dma1 5>, <&dma1 5>;
			dma-names	= "tx", "rx";
			playback-cma	= <128>;
			capture-cma	= <128>;
			tx-fifo-size	= <128>;
			rx-fifo-size	= <128>;
			status = "disabled";
		};

		daudio2_mach:daudio2_mach{
			compatible = "allwinner,sunxi-snd-mach";
			soundcard-mach,name		= "snddaudio2";
			soundcard-mach,format		= "i2s";
			soundcard-mach,slot-num		= <2>;
			soundcard-mach,slot-width	= <32>;
			status = "disabled";
			soundcard-mach,cpu {
				sound-dai = <&daudio2_plat>;
			};
			soundcard-mach,codec {
			};
		};

		daudio3_plat:daudio3_plat@7115000 {
			#sound-dai-cells = <0>;
			compatible = "allwinner,sunxi-snd-plat-daudio";
			reg		= <0x0 0x07115000 0x0 0xA0>;
			resets		= <&dsp_ccu RST_BUS_DSP_I2S3>;
			clocks		= <&dsp_ccu CLK_BUS_DSP_I2S3>,
					  <&dsp_ccu CLK_PLL_DSP_AUDIO1_DIV2>,
					  <&dsp_ccu CLK_PLL_DSP_AUDIO1_DIV5>,
					  <&ccu CLK_PLL_AUDIO0_4X>,
					  <&ccu CLK_PLL_PERI1_600M>,
					  <&dsp_ccu CLK_DSP_I2S3_ASRC>,
					  <&dsp_ccu CLK_DSP_I2S3>;
			clock-names	= "clk_bus_i2s",
					  "clk_pll_audio1_d2",
					  "clk_pll_audio1_d5",
					  "clk_pll_audio0_4x",
					  "clk_pll_peri1_600",
					  "clk_i2s_asrc",
					  "clk_i2s";
			dmas		= <&dma1 6>, <&dma1 6>;
			dma-names	= "tx", "rx";
			playback-cma	= <128>;
			capture-cma	= <128>;
			tx-fifo-size	= <128>;
			rx-fifo-size	= <128>;
			status = "disabled";
		};

		daudio3_mach:daudio3_mach{
			compatible = "allwinner,sunxi-snd-mach";
			soundcard-mach,name		= "snddaudio3";
			soundcard-mach,format		= "i2s";
			soundcard-mach,slot-num		= <2>;
			soundcard-mach,slot-width	= <32>;
			status = "disabled";
			soundcard-mach,cpu {
				sound-dai = <&daudio3_plat>;
			};
			soundcard-mach,codec {
			};
		};

		/* audio dirver module -> spdif */
		spdif_plat:spdif_plat@7116000 {
			#sound-dai-cells = <0>;
			compatible	= "allwinner,sunxi-snd-plat-spdif";
			reg		= <0x0 0x07116000 0x0 0x58>;
			resets		= <&dsp_ccu RST_BUS_DSP_SPDIF>;
			clocks		= <&dsp_ccu CLK_BUS_DSP_SPDIF>,
					  <&dsp_ccu CLK_PLL_DSP_AUDIO1_DIV2>,
					  <&dsp_ccu CLK_PLL_DSP_AUDIO1_DIV5>,
					  <&ccu CLK_PLL_AUDIO0_4X>,
					  <&ccu CLK_PLL_PERI1_600M>,
					  <&dsp_ccu CLK_DSP_SPDIF_TX>,
					  <&dsp_ccu CLK_DSP_SPDIF_RX>;
			clock-names	= "clk_bus_spdif",
					  "clk_pll_audio1_d2",
					  "clk_pll_audio1_d5",
					  "clk_pll_audio0_4x",
					  "clk_pll_peri1_600",
					  "clk_spdif_tx",
					  "clk_spdif_rx";
			dmas		= <&dma1 2>, <&dma1 2>;
			dma-names	= "tx", "rx";
			playback-cma	= <128>;
			capture-cma	= <128>;
			tx-fifo-size	= <128>;
			rx-fifo-size	= <128>;
			status = "disabled";
		};

		spdif_mach:spdif_mach {
			compatible = "allwinner,sunxi-snd-mach";
			soundcard-mach,name = "sndspdif";
			status = "disabled";
			soundcard-mach,cpu {
				sound-dai = <&spdif_plat>;
			};
			soundcard-mach,codec {
			};
		};
		/* audio dirver module -> END */

		usbc0:usbc0@0 {
			device_type = "usbc0";
			compatible = "allwinner,sunxi-otg-manager";
			usb_port_type = <2>;
			usb_detect_type = <1>;
			usb_detect_mode = <0>;
			usb_id_gpio;
			usb_det_vbus_gpio;
			usb_regulator_io = "nocare";
			usb_wakeup_suspend = <0>;
			usb_luns = <3>;
			usb_serial_unique = <0>;
			usb_serial_number = "20080411";
			rndis_wceis = <1>;
			status = "disabled";
		};

		udc:udc-controller@4100000 {
			compatible = "allwinner,sunxi-udc";
			reg = <0x0 0x04100000 0x0 0x1000>, /*udc base*/
			      <0x0 0x00000000 0x0 0x100>; /*sram base*/
			interrupts = <GIC_SPI 29 IRQ_TYPE_LEVEL_HIGH>;
			clocks = <&ccu CLK_USBOTG0>;
			clock-names = "bus_otg";
			resets = <&ccu RST_USB_OTG0>, <&ccu RST_USB_PHY0_RSTN>;
			reset-names = "otg", "phy";
			status = "disabled";
		};

		ehci0:ehci0-controller@4101000 {
			compatible = "allwinner,sunxi-ehci0";
			reg = <0x0 0x04101000 0x0 0xFFF>, /*hci0 base*/
			      <0x0 0x00000000 0x0 0x100>, /*sram base*/
			      <0x0 0x04100000 0x0 0x1000>; /*otg base*/
			interrupts = <GIC_SPI 30 IRQ_TYPE_LEVEL_HIGH>;
			clocks = <&ccu CLK_USBEHCI0>;
			clock-names = "bus_hci";
			resets = <&ccu RST_USB_EHCI0>, <&ccu RST_USB_PHY0_RSTN>;
			reset-names = "hci", "phy";
			hci_ctrl_no = <0>;
			status = "disabled";
		};

		ohci0:ohci0-controller@4101400 {
			compatible = "allwinner,sunxi-ohci0";
			reg = <0x0 0x04101400 0x0 0xFFF>, /*hci0 base*/
			      <0x0 0x00000000 0x0 0x100>, /*sram base*/
			      <0x0 0x04100000 0x0 0x1000>; /*otg base*/
			interrupts = <GIC_SPI 31 IRQ_TYPE_LEVEL_HIGH>;
			clocks = <&ccu CLK_USBOHCI0>, <&ccu CLK_USB0>;
			clock-names = "bus_hci", "ohci";
			resets = <&ccu RST_USB_OHCI0>, <&ccu RST_USB_PHY0_RSTN>;
			reset-names = "hci", "phy";
			hci_ctrl_no = <0>;
			status = "disabled";
		};
		usbc2:usbc2@0 {
			compatible = "allwinner,sun55i-a523-dwc3";
			status = "disabled";
		};

		xhci2: xhci2-controller@4D00000 {
			compatible = "snps,dwc3";
			reg = <0x0 0x04D00000 0x0 0x1007FF>;
			interrupts = <GIC_SPI 35 IRQ_TYPE_LEVEL_HIGH>;
			dr_mode = "host"; // dr_mode option：host,peripheral,otg
			//clocks = <&ccu CLK_USB3>, <&ccu CLK_USB3_REF>, <&ccu CLK_USB2_REF>, <&ccu CLK_USB3_SUSPEND>;
			//clock-names = "bus_clk", "ref_clk3", "ref_clk2", "suspend";
			//resets = <&ccu RST_USB_3>, <&ccu RST_BUS_PCIE_USB3>;
			//reset-names = "hci", "phy";
			snps,dis_u3_susphy_quirk;
			snps,dis_u2_susphy_quirk;
			status = "disabled";
		};

		hwspinlock: hwspinlock@3005000 {
			compatible = "allwinner,sunxi-hwspinlock";
			reg = <0x0 0x3005000 0x0 0x1000>;
			#hwlock-cells = <1>;
			clocks = <&ccu CLK_SPINLOCK>;
			clock-names = "clk_hwspinlock_bus";
			resets = <&ccu RST_BUS_SPINLOCK>;
			reset-names = "rst";
			num-locks = <32>;
			status = "okay";
		};

		/* test for AMP mailbox */
		mailbox_test: mailbox_test@0 {
			compatible = "mailbox-test";
			reg = <0x0 0x03000008 0x0 0x04>;
			mboxes = <&msgbox 8>, <&msgbox 9>;
			mbox-names = "tx", "rx";
			status = "disabled";
		};

		/*
		 * Some bitfile doesn't have riscv part.
		 * When use such bitfile, remember to delete
		 * riscv reg and irq in msgbox dts node,
		 * otherwise may cause Linux stuck.
		 * In the same time, adjust sun55iw3 hwdata's
		 * processors_max to 3, and mbox_num_chans to 8
		 * in msgbox driver.
		 */
		msgbox: msgbox@3003000 {
			compatible = "allwinner,sun55iw3-msgbox";
			#mbox-cells = <1>;
			reg = <0x0 0x03003000 0x0 0x1000>,
			      <0x0 0x07120000 0x0 0x1000>,
			      <0x0 0x07094000 0x0 0x1000>,
			      <0x0 0x07136000 0x0 0x1000>;
			interrupts = <GIC_SPI 0 IRQ_TYPE_LEVEL_HIGH>,
					<GIC_SPI 1 IRQ_TYPE_LEVEL_HIGH>,
					<GIC_SPI 181 IRQ_TYPE_LEVEL_HIGH>,
					<GIC_SPI 174 IRQ_TYPE_LEVEL_HIGH>;
			clocks = <&ccu CLK_MSGBOX0>;
			resets = <&ccu RST_BUS_MSGBOX0>;
			reset-names = "rst";
			local_id = <0>;
		};

		dsp0_rproc: dsp0_rproc@0 {
			compatible = "allwinner,hifi4-rproc";
			clock-frequency = <600000000>;
			clocks = <&ccu CLK_PLL_PERI0_2X>, <&ccu CLK_DSP>, <&dsp_ccu CLK_BUS_DSP_CFG>, <&r_ccu CLK_R_AHB>;
			clock-names = "pll", "mod", "cfg", "ahbs";
			resets = <&dsp_ccu RST_BUS_DSP>, <&dsp_ccu RST_BUS_DSP_CFG>, <&dsp_ccu RST_BUS_DSP_DBG>;
			reset-names = "mod-rst", "cfg-rst", "dbg-rst";
			reg = <0x0 0x07010364 0x0 0x04>,
				<0x0 0x07100000 0x0 0x40>;
			reg-names = "sram-for-cpux", "hifi4-cfg";
			mboxes = <&msgbox 4>;
			mbox-names = "arm-kick";
			memory-region = <&dsp0ddr_reserved>, <&vdev0buffer>, <&vdev0vring0>, <&vdev0vring1>,
					<&dsp0iram_reserved>, <&dsp0dram0_reserved>, <&dsp0dram1_reserved>;
			memory-mappings =
				/* < DA		len		PA >	*/
				/* local SRAM via external bus */
				< 0x20000	0x20000		0x20000 >,
				/* local SRAM via internal bus */
				< 0x400000	0x10000		0x400000 >,
				< 0x420000	0x8000		0x420000 >,
				< 0x440000	0x8000		0x440000 >,
				/* DDR front 256MB */
				< 0x10000000	0x10000000	0x40000000 >,
				/* local SRAM via internal bus */
				< 0x20020000	0x10000		0x400000 >,
				< 0x20030000	0x8000		0x420000 >,
				< 0x20038000	0x8000		0x440000 >,

				/* DDR front 256MB */
				< 0x30000000	0x10000000	0x40000000 >,
				/* DDR front 1GB */
				< 0x40000000	0x40000000	0x40000000 >,
				/* DDR front 1GB */
				< 0x80000000	0x40000000	0x40000000 >,
				/* DDR front 1GB */
				< 0xC0000000	0x40000000	0x40000000 >;
			id = <0>;
			status = "disabled";
		};

		e906_rproc: e906_rproc@0 {
			compatible = "allwinner,e906-rproc";
			clocks = <&dsp_ccu CLK_BUS_PUBSRAM>, <&dsp_ccu CLK_BUS_RV>, <&dsp_ccu CLK_BUS_RV_CFG>;
			clock-names = "pubsram", "mod", "cfg";
			resets = <&dsp_ccu RST_BUS_PUBSRAM>, <&dsp_ccu RST_BUS_RV>, <&dsp_ccu RST_BUS_RV_CFG>, <&dsp_ccu RST_BUS_RV_DBG>;
			reset-names = "pubsram-rst", "mod-rst", "cfg-rst", "dbg-rst";
			reg = <0x0 0x07130000 0x0 0x1000>;
			reg-names = "e906-cfg";
			mboxes = <&msgbox 8>;
			mbox-names = "arm-kick";
			memory-region = <&riscvsram0_reserved>, <&riscvsram1_reserved>, <&vdev0buffer>, <&vdev0vring0>, <&vdev0vring1>;
			memory-mappings =
				/* < DA		len		PA >	*/
				/* DSP RAM */
				< 0x20000	0x20000		0x20000 >,
				/* SRAM A2 */
				< 0x40000	0x24000		0x40000 >,
				/* DDR */
				< 0x8000000	0x37f00000	0x8000000 >,
				/* SRAM SPACE 0 */
				< 0x3ffc0000	0x40000		0x07280000 >,
				/* SRAM SPACE 1 */
				< 0x40000000	0x40000		0x072c0000 >,
				/* DRAM SPACE */
				< 0x40040000	0x3ffc0000	0x40040000>;
			id = <0>;
			status = "okay";
		};

		rpbuf_controller0: rpbuf_controller@0 {
			compatible = "allwinner,rpbuf-controller";
			remoteproc = <&dsp0_rproc>;
			ctrl_id = <0>;	/* index of /dev/rpbuf_ctrl */
			//iommus = <&mmu_aw 5 1>;
			memory-region = <&dsp0_rpbuf_reserved>;
			status = "disabled";
		};

		vind0: vind@5800800 {
			compatible = "allwinner,sunxi-vin-media", "simple-bus";
			#address-cells = <2>;
			#size-cells = <2>;
			ranges;
			device_id = <0>;
			csi_top = <336000000>;
			csi_isp = <327000000>;
			reg = <0x0 0x05800800 0x0 0x200>,
				<0x0 0x05800000 0x0 0x800>,
				<0x0 0x05810000 0x0 0x100>;
			interrupts = <GIC_SPI 139 IRQ_TYPE_LEVEL_HIGH>;
			clocks = <>, <>,
				<>, <>, <>,
				<>, <>, <>,
				<>, <>,
				<>, <>, <>;
			clock-names = "csi_top", "csi_top_src",
					"csi_mclk0", "csi_mclk0_24m", "csi_mclk0_pll",
					"csi_mclk1", "csi_mclk1_24m", "csi_mclk1_pll",
					"csi_isp", "csi_isp_src",
					"csi_bus", "csi_mbus", "csi_isp_mbus";
			resets = <>, <>;
			reset-names = "csi_ret","isp_ret";
			pinctrl-names = "mclk0-default","mclk0-sleep","mclk1-default","mclk1-sleep";
			pinctrl-0 = <>;
			pinctrl-1 = <>;
			pinctrl-2 = <>;
			pinctrl-3 = <>;
			status = "okay";

			csi0: csi@5820000 {
				compatible = "allwinner,sunxi-csi";
				reg = <0x0 0x05820000 0x0 0x1000>;
				interrupts = <GIC_SPI 130 IRQ_TYPE_LEVEL_HIGH>;
				device_id = <0>;
				status = "okay";
			};
			csi1: csi@5821000 {
				compatible = "allwinner,sunxi-csi";
				reg = <0x0 0x05821000 0x0 0x1000>;
				interrupts = <GIC_SPI 131 IRQ_TYPE_LEVEL_HIGH>;
				device_id = <1>;
				status = "okay";
			};
			csi2: csi@5822000 {
				compatible = "allwinner,sunxi-csi";
				reg = <0x0 0x05822000 0x0 0x1000>;
				interrupts = <GIC_SPI 132 IRQ_TYPE_LEVEL_HIGH>;
				device_id = <2>;
				status = "okay";
			};
			csi3: csi@5823000 {
				compatible = "allwinner,sunxi-csi";
				reg = <0x0 0x05823000 0x0 0x1000>;
				interrupts = <GIC_SPI 147 IRQ_TYPE_LEVEL_HIGH>;
				device_id = <3>;
				status = "okay";
			};
			mipi0: mipi@5810100 {
				compatible = "allwinner,sunxi-mipi";
				reg = <0x0 0x05810100 0x0 0x100>,
					<0x0 0x05811000 0x0 0x400>;
				interrupts = <GIC_SPI 137 IRQ_TYPE_LEVEL_HIGH>;
				device_id = <0>;
				status = "okay";
			};
			mipi1: mipi@5810200 {
				compatible = "allwinner,sunxi-mipi";
				reg = <0x0 0x05810200 0x0 0x100>,
					<0x0 0x05811400 0x0 0x400>;
				device_id = <1>;
				status = "okay";
			};
			mipi2: mipi@5810300 {
				compatible = "allwinner,sunxi-mipi";
				reg = <0x0 0x05810300 0x0 0x100>,
					<0x0 0x05811800 0x0 0x400>;
				device_id = <2>;
				status = "okay";
			};
			mipi3: mipi@5810400 {
				compatible = "allwinner,sunxi-mipi";
				reg = <0x0 0x05810400 0x0 0x100>,
					<0x0 0x05811C00 0x0 0x400>;
				device_id = <3>;
				status = "okay";
			};
			tdm0: tdm@5908000 {
				compatible = "allwinner,sunxi-tdm";
				reg = <0x0 0x05908000 0x0 0x300>;
				interrupts = <GIC_SPI 138 IRQ_TYPE_LEVEL_HIGH>;
				work_mode = <0x0>;
				device_id = <0>;
				iommus = <&mmu_aw 0 0>;
				status = "okay";
			};
			isp00:isp@5900000 {
				compatible = "allwinner,sunxi-isp";
				reg = <0x0 0x05900000 0x0 0x1300>;
				interrupts = <GIC_SPI 133 IRQ_TYPE_LEVEL_HIGH>;
				work_mode = <0x0>;
				device_id = <0>;
				iommus = <&mmu_aw 0 0>;
				status = "okay";
			};
			isp01:isp@58ffffc {
				compatible = "allwinner,sunxi-isp";
				reg = <0x0 0x058ffffc 0x0 0x1304>;
				interrupts = <GIC_SPI 134 IRQ_TYPE_LEVEL_HIGH>;
				work_mode = <0xff>;
				device_id = <1>;
				iommus = <&mmu_aw 0 0>;
				status = "okay";
			};
			isp02:isp@58ffff8 {
				compatible = "allwinner,sunxi-isp";
				reg = <0x0 0x058ffff8 0x0 0x1308>;
				interrupts = <GIC_SPI 135 IRQ_TYPE_LEVEL_HIGH>;
				work_mode = <0xff>;
				device_id = <2>;
				iommus = <&mmu_aw 0 0>;
				status = "okay";
			};
			isp03:isp@58ffff4 {
				compatible = "allwinner,sunxi-isp";
				reg = <0x0 0x058ffff4 0x0 0x130c>;
				interrupts = <GIC_SPI 136 IRQ_TYPE_LEVEL_HIGH>;
				work_mode = <0xff>;
				device_id = <3>;
				iommus = <&mmu_aw 0 0>;
				status = "okay";
			};
			isp10:isp@4 {
				compatible = "allwinner,sunxi-isp";
				device_id = <4>;
				iommus = <&mmu_aw 0 0>;
				status = "okay";
			};
			scaler00:scaler@5910000 {
				compatible = "allwinner,sunxi-scaler";
				reg = <0x0 0x05910000 0x0 0x400>;
				interrupts = <GIC_SPI 126 IRQ_TYPE_LEVEL_HIGH>;
				work_mode = <0x0>;
				device_id = <0>;
				iommus = <&mmu_aw 1 0>;
				status = "okay";
			};
			scaler01:scaler@590fffc {
				compatible = "allwinner,sunxi-scaler";
				reg = <0x0 0x0590fffc 0x0 0x404>;
				work_mode = <0xff>;
				device_id = <1>;
				iommus = <&mmu_aw 1 0>;
				status = "okay";
			};
			scaler02:scaler@590fff8 {
				compatible = "allwinner,sunxi-scaler";
				reg = <0x0 0x0590fff8 0x0 0x408>;
				work_mode = <0xff>;
				device_id = <2>;
				iommus = <&mmu_aw 1 0>;
				status = "okay";
			};
			scaler03:scaler@590fff4 {
				compatible = "allwinner,sunxi-scaler";
				reg = <0x0 0x0590fff4 0x0 0x40c>;
				work_mode = <0xff>;
				device_id = <3>;
				iommus = <&mmu_aw 1 0>;
				status = "okay";
			};
			scaler10:scaler@5910400 {
				compatible = "allwinner,sunxi-scaler";
				reg = <0x0 0x05910400 0x0 0x400>;
				interrupts = <GIC_SPI 127 IRQ_TYPE_LEVEL_HIGH>;
				work_mode = <0x0>;
				device_id = <4>;
				iommus = <&mmu_aw 1 0>;
				status = "okay";
			};
			scaler11:scaler@59103fc {
				compatible = "allwinner,sunxi-scaler";
				reg = <0x0 0x059103fc 0x0 0x404>;
				work_mode = <0xff>;
				device_id = <5>;
				iommus = <&mmu_aw 1 0>;
				status = "okay";
			};
			scaler12:scaler@59103f8 {
				compatible = "allwinner,sunxi-scaler";
				reg = <0x0 0x059103f8 0x0 0x408>;
				work_mode = <0xff>;
				device_id = <6>;
				iommus = <&mmu_aw 1 0>;
				status = "okay";
			};
			scaler13:scaler@59103f4 {
				compatible = "allwinner,sunxi-scaler";
				reg = <0x0 0x059103f4 0x0 0x40c>;
				work_mode = <0xff>;
				device_id = <7>;
				iommus = <&mmu_aw 1 0>;
				status = "okay";
			};
			scaler20:scaler@5910800 {
				compatible = "allwinner,sunxi-scaler";
				reg = <0x0 0x05910800 0x0 0x400>;
				interrupts = <GIC_SPI 128 IRQ_TYPE_LEVEL_HIGH>;
				work_mode = <0x0>;
				device_id = <8>;
				iommus = <&mmu_aw 1 0>;
				status = "okay";
			};
			scaler21:scaler@59107fc {
				compatible = "allwinner,sunxi-scaler";
				reg = <0x0 0x059107fc 0x0 0x404>;
				work_mode = <0xff>;
				device_id = <9>;
				iommus = <&mmu_aw 1 0>;
				status = "okay";
			};
			scaler22:scaler@59107f8 {
				compatible = "allwinner,sunxi-scaler";
				reg = <0x0 0x059107f8 0x0 0x408>;
				work_mode = <0xff>;
				device_id = <10>;
				iommus = <&mmu_aw 1 0>;
				status = "okay";
			};
			scaler23:scaler@59107f4 {
				compatible = "allwinner,sunxi-scaler";
				reg = <0x0 0x059107f4 0x0 0x40c>;
				work_mode = <0xff>;
				device_id = <11>;
				iommus = <&mmu_aw 1 0>;
				status = "okay";
			};
			scaler30:scaler@5910c00 {
				compatible = "allwinner,sunxi-scaler";
				reg = <0x0 0x05910c00 0x0 0x400>;
				interrupts = <GIC_SPI 129 IRQ_TYPE_LEVEL_HIGH>;
				work_mode = <0x0>;
				device_id = <12>;
				iommus = <&mmu_aw 1 0>;
				status = "okay";
			};
			scaler31:scaler@5910bfc {
				compatible = "allwinner,sunxi-scaler";
				reg = <0x0 0x05910bfc 0x0 0x404>;
				work_mode = <0xff>;
				device_id = <13>;
				iommus = <&mmu_aw 1 0>;
				status = "okay";
			};
			scaler32:scaler@5910bf8 {
				compatible = "allwinner,sunxi-scaler";
				reg = <0x0 0x05910bf8 0x0 0x408>;
				work_mode = <0xff>;
				device_id = <14>;
				iommus = <&mmu_aw 1 0>;
				status = "okay";
			};
			scaler33:scaler@5910bf4 {
				compatible = "allwinner,sunxi-scaler";
				reg = <0x0 0x05910bf4 0x0 0x40c>;
				work_mode = <0xff>;
				device_id = <15>;
				iommus = <&mmu_aw 1 0>;
				status = "okay";
			};
			scaler40:scaler@16 {
				compatible = "allwinner,sunxi-scaler";
				device_id = <16>;
				iommus = <&mmu_aw 1 0>;
				status = "okay";
			};
			scaler50:scaler@17 {
				compatible = "allwinner,sunxi-scaler";
				device_id = <17>;
				iommus = <&mmu_aw 1 0>;
				status = "okay";
			};
			actuator0: actuator@2108180 {
				compatible = "allwinner,sunxi-actuator";
				device_type = "actuator0";
				reg = <0x0 0x02108180 0x0 0x10>;
				actuator0_name = "ad5820_act";
				actuator0_slave = <0x18>;
				actuator0_af_pwdn = <>;
				actuator0_afvdd = "afvcc-csi";
				actuator0_afvdd_vol = <2800000>;
				status = "disabled";
			};
			flash0: flash@2108190 {
				device_type = "flash0";
				compatible = "allwinner,sunxi-flash";
				reg = <0x0 0x02108190 0x0 0x10>;
				flash0_type = <2>;
				flash0_en = <>;
				flash0_mode = <>;
				flash0_flvdd = "";
				flash0_flvdd_vol = <>;
				device_id = <0>;
				status = "disabled";
			};
			sensor0: sensor@5812000 {
				reg = <0x0 0x05812000 0x0 0x10>;
				device_type = "sensor0";
				compatible = "allwinner,sunxi-sensor";
				sensor0_mname = "ov5640";
				sensor0_twi_cci_id = <2>;
				sensor0_twi_addr = <0x78>;
				sensor0_mclk_id = <0>;
				sensor0_pos = "rear";
				sensor0_isp_used = <0>;
				sensor0_fmt = <0>;
				sensor0_stby_mode = <0>;
				sensor0_vflip = <0>;
				sensor0_hflip = <0>;
				sensor0_iovdd-supply = <>;
				sensor0_iovdd_vol = <>;
				sensor0_avdd-supply = <>;
				sensor0_avdd_vol = <>;
				sensor0_dvdd-supply = <>;
				sensor0_dvdd_vol = <>;
				sensor0_power_en = <>;
				sensor0_reset = <>;
				sensor0_pwdn = <>;
				sensor0_sm_vs = <>;
				flash_handle = <&flash0>;
				act_handle = <&actuator0>;
				device_id = <0>;
				status	= "disabled";
			};
			sensor1: sensor@5812010 {
				reg = <0x0 0x05812010 0x0 0x10>;
				device_type = "sensor1";
				compatible = "allwinner,sunxi-sensor";
				sensor1_mname = "ov5647";
				sensor1_twi_cci_id = <3>;
				sensor1_twi_addr = <0x6c>;
				sensor1_mclk_id = <1>;
				sensor1_pos = "front";
				sensor1_isp_used = <0>;
				sensor1_fmt = <0>;
				sensor1_stby_mode = <0>;
				sensor1_vflip = <0>;
				sensor1_hflip = <0>;
				sensor1_iovdd-supply = <>;
				sensor1_iovdd_vol = <>;
				sensor1_avdd-supply = <>;
				sensor1_avdd_vol = <>;
				sensor1_dvdd-supply = <>;
				sensor1_dvdd_vol = <>;
				sensor1_power_en = <>;
				sensor1_reset = <>;
				sensor1_pwdn = <>;
				sensor1_sm_vs = <>;
				flash_handle = <>;
				act_handle = <>;
				device_id = <1>;
				status	= "disabled";
			};
			vinc00:vinc@5830000 {
				device_type = "vinc0";
				compatible = "allwinner,sunxi-vin-core";
				reg = <0x0 0x05830000 0x0 0x1000>;
				interrupts = <GIC_SPI 122 IRQ_TYPE_LEVEL_HIGH>;
				vinc0_csi_sel = <3>;
				vinc0_mipi_sel = <0xff>;
				vinc0_isp_sel = <0>;
				vinc0_isp_tx_ch = <0>;
				vinc0_tdm_rx_sel = <0>;
				vinc0_rear_sensor_sel = <0>;
				vinc0_front_sensor_sel = <0>;
				vinc0_sensor_list = <0>;
				device_id = <0>;
				work_mode = <0x0>;
				iommus = <&mmu_aw 1 0>;
				status = "okay";
			};

			vinc01:vinc@582fffc {
				device_type = "vinc1";
				compatible = "allwinner,sunxi-vin-core";
				reg = <0x0 0x0582fffc 0x0 0x1004>;
				vinc1_csi_sel = <2>;
				vinc1_mipi_sel = <0xff>;
				vinc1_isp_sel = <1>;
				vinc1_isp_tx_ch = <1>;
				vinc1_tdm_rx_sel = <1>;
				vinc1_rear_sensor_sel = <0>;
				vinc1_front_sensor_sel = <0>;
				vinc1_sensor_list = <0>;
				device_id = <1>;
				work_mode = <0xff>;
				iommus = <&mmu_aw 1 0>;
				status = "disabled";
			};
			vinc02:vinc@582fff8 {
				device_type = "vinc2";
				compatible = "allwinner,sunxi-vin-core";
				reg = <0x0 0x0582fff8 0x0 0x1008>;
				vinc2_csi_sel = <2>;
				vinc2_mipi_sel = <0xff>;
				vinc2_isp_sel = <2>;
				vinc2_isp_tx_ch = <2>;
				vinc2_tdm_rx_sel = <2>;
				vinc2_rear_sensor_sel = <0>;
				vinc2_front_sensor_sel = <0>;
				vinc2_sensor_list = <0>;
				device_id = <2>;
				work_mode = <0xff>;
				iommus = <&mmu_aw 1 0>;
				status = "disabled";
			};

			vinc03:vinc@582fff4 {
				device_type = "vinc3";
				compatible = "allwinner,sunxi-vin-core";
				reg = <0x0 0x0582fff4 0x0 0x100c>;
				vinc3_csi_sel = <0>;
				vinc3_mipi_sel = <0xff>;
				vinc3_isp_sel = <0>;
				vinc3_isp_tx_ch = <0>;
				vinc3_tdm_rx_sel = <0>;
				vinc3_rear_sensor_sel = <1>;
				vinc3_front_sensor_sel = <1>;
				vinc3_sensor_list = <0>;
				device_id = <3>;
				work_mode = <0xff>;
				iommus = <&mmu_aw 1 0>;
				status = "disabled";
			};

			vinc10:vinc@5831000 {
				device_type = "vinc4";
				compatible = "allwinner,sunxi-vin-core";
				reg = <0x0 0x05831000 0x0 0x1000>;
				interrupts = <GIC_SPI 123 IRQ_TYPE_LEVEL_HIGH>;
				vinc4_csi_sel = <3>;
				vinc4_mipi_sel = <0xff>;
				vinc4_isp_sel = <0>;
				vinc4_isp_tx_ch = <0>;
				vinc4_tdm_rx_sel = <1>;
				vinc4_rear_sensor_sel = <0>;
				vinc4_front_sensor_sel = <0>;
				vinc4_sensor_list = <0>;
				device_id = <4>;
				work_mode = <0x0>;
				iommus = <&mmu_aw 1 0>;
				status = "disabled";
			};

			vinc11:vinc@5830ffc {
				device_type = "vinc5";
				compatible = "allwinner,sunxi-vin-core";
				reg = <0x0 0x05830ffc 0x0 0x1004>;
				vinc5_csi_sel = <2>;
				vinc5_mipi_sel = <0xff>;
				vinc5_isp_sel = <1>;
				vinc5_isp_tx_ch = <1>;
				vinc5_tdm_rx_sel = <1>;
				vinc5_rear_sensor_sel = <0>;
				vinc5_front_sensor_sel = <0>;
				vinc5_sensor_list = <0>;
				device_id = <5>;
				work_mode = <0xff>;
				iommus = <&mmu_aw 1 0>;
				status = "disabled";
			};

			vinc12:vinc@5830ff8 {
				device_type = "vinc6";
				compatible = "allwinner,sunxi-vin-core";
				reg = <0x0 0x05830ff8 0x0 0x1008>;
				vinc6_csi_sel = <2>;
				vinc6_mipi_sel = <0xff>;
				vinc6_isp_sel = <0>;
				vinc6_isp_tx_ch = <0>;
				vinc6_tdm_rx_sel = <0>;
				vinc6_rear_sensor_sel = <0>;
				vinc6_front_sensor_sel = <0>;
				vinc6_sensor_list = <0>;
				device_id = <6>;
				work_mode = <0xff>;
				iommus = <&mmu_aw 1 0>;
				status = "disabled";
			};

			vinc13:vinc@5830ff4 {
				device_type = "vinc7";
				compatible = "allwinner,sunxi-vin-core";
				reg = <0x0 0x05830ff4 0x0 0x100c>;
				vinc7_csi_sel = <2>;
				vinc7_mipi_sel = <0xff>;
				vinc7_isp_sel = <0>;
				vinc7_isp_tx_ch = <0>;
				vinc7_tdm_rx_sel = <0>;
				vinc7_rear_sensor_sel = <0>;
				vinc7_front_sensor_sel = <0>;
				vinc7_sensor_list = <0>;
				device_id = <7>;
				work_mode = <0xff>;
				iommus = <&mmu_aw 1 0>;
				status = "disabled";
			};

			vinc20:vinc@5832000 {
				device_type = "vinc8";
				compatible = "allwinner,sunxi-vin-core";
				reg = <0x0 0x05832000 0x0 0x1000>;
				interrupts = <GIC_SPI 124 IRQ_TYPE_LEVEL_HIGH>;
				vinc8_csi_sel = <2>;
				vinc8_mipi_sel = <0xff>;
				vinc8_isp_sel = <4>;
				vinc8_isp_tx_ch = <3>;
				vinc8_tdm_rx_sel = <3>;
				vinc8_rear_sensor_sel = <0>;
				vinc8_front_sensor_sel = <0>;
				vinc8_sensor_list = <0>;
				device_id = <8>;
				work_mode = <0x0>;
				iommus = <&mmu_aw 1 0>;
				status = "disabled";
			};

			vinc21:vinc@5831ffc {
				device_type = "vinc9";
				compatible = "allwinner,sunxi-vin-core";
				reg = <0x0 0x05831ffc 0x0 0x1004>;
				vinc9_csi_sel = <2>;
				vinc9_mipi_sel = <0xff>;
				vinc9_isp_sel = <0>;
				vinc9_isp_tx_ch = <0>;
				vinc9_tdm_rx_sel = <0>;
				vinc9_rear_sensor_sel = <0>;
				vinc9_front_sensor_sel = <0>;
				vinc9_sensor_list = <0>;
				device_id = <9>;
				work_mode = <0xff>;
				iommus = <&mmu_aw 1 0>;
				status = "disabled";
			};

			vinc22:vinc@5831ff8 {
				device_type = "vinc10";
				compatible = "allwinner,sunxi-vin-core";
				reg = <0x0 0x05831ff8 0x0 0x1008>;
				vinc10_csi_sel = <2>;
				vinc10_mipi_sel = <0xff>;
				vinc10_isp_sel = <0>;
				vinc10_isp_tx_ch = <0>;
				vinc10_tdm_rx_sel = <0>;
				vinc10_rear_sensor_sel = <0>;
				vinc10_front_sensor_sel = <0>;
				vinc10_sensor_list = <0>;
				device_id = <10>;
				work_mode = <0xff>;
				iommus = <&mmu_aw 1 0>;
				status = "disabled";
			};

			vinc23:vinc@5831ff4 {
				device_type = "vinc11";
				compatible = "allwinner,sunxi-vin-core";
				reg = <0x0 0x05831ff4 0x0 0x100c>;
				vinc11_csi_sel = <2>;
				vinc11_mipi_sel = <0xff>;
				vinc11_isp_sel = <0>;
				vinc11_isp_tx_ch = <0>;
				vinc11_tdm_rx_sel = <0>;
				vinc11_rear_sensor_sel = <0>;
				vinc11_front_sensor_sel = <0>;
				vinc11_sensor_list = <0>;
				device_id = <11>;
				work_mode = <0xff>;
				iommus = <&mmu_aw 1 0>;
				status = "disabled";
			};

			vinc30:vinc@5833000 {
				device_type = "vinc12";
				compatible = "allwinner,sunxi-vin-core";
				reg = <0x0 0x05833000 0x0 0x1000>;
				interrupts = <GIC_SPI 125 IRQ_TYPE_LEVEL_HIGH>;
				vinc12_csi_sel = <2>;
				vinc12_mipi_sel = <0xff>;
				vinc12_isp_sel = <0>;
				vinc12_isp_tx_ch = <0>;
				vinc12_tdm_rx_sel = <0>;
				vinc12_rear_sensor_sel = <0>;
				vinc12_front_sensor_sel = <0>;
				vinc12_sensor_list = <0>;
				device_id = <12>;
				work_mode = <0x0>;
				iommus = <&mmu_aw 1 0>;
				status = "disabled";
			};

			vinc31:vinc@5832ffc {
				device_type = "vinc13";
				compatible = "allwinner,sunxi-vin-core";
				reg = <0x0 0x05832ffc 0x0 0x1004>;
				vinc13_csi_sel = <2>;
				vinc13_mipi_sel = <0xff>;
				vinc13_isp_sel = <0>;
				vinc13_isp_tx_ch = <0>;
				vinc13_tdm_rx_sel = <0>;
				vinc13_rear_sensor_sel = <0>;
				vinc13_front_sensor_sel = <0>;
				vinc13_sensor_list = <0>;
				device_id = <13>;
				work_mode = <0xff>;
				iommus = <&mmu_aw 1 0>;
				status = "disabled";
			};

			vinc32:vinc@5832ff8 {
				device_type = "vinc14";
				compatible = "allwinner,sunxi-vin-core";
				reg = <0x0 0x05832ff8 0x0 0x1008>;
				vinc14_csi_sel = <2>;
				vinc14_mipi_sel = <0xff>;
				vinc14_isp_sel = <0>;
				vinc14_isp_tx_ch = <0>;
				vinc14_tdm_rx_sel = <0>;
				vinc14_rear_sensor_sel = <0>;
				vinc14_front_sensor_sel = <0>;
				vinc14_sensor_list = <0>;
				device_id = <14>;
				work_mode = <0xff>;
				iommus = <&mmu_aw 1 0>;
				status = "disabled";
			};

			vinc33:vinc@5832ff4 {
				device_type = "vinc15";
				compatible = "allwinner,sunxi-vin-core";
				reg = <0x0 0x05832ff4 0x0 0x100c>;
				vinc15_csi_sel = <2>;
				vinc15_mipi_sel = <0xff>;
				vinc15_isp_sel = <0>;
				vinc15_isp_tx_ch = <0>;
				vinc15_tdm_rx_sel = <0>;
				vinc15_rear_sensor_sel = <0>;
				vinc15_front_sensor_sel = <0>;
				vinc15_sensor_list = <0>;
				device_id = <15>;
				work_mode = <0xff>;
				iommus = <&mmu_aw 1 0>;
				status = "disabled";
			};

			vinc40:vinc@5834000 {
				device_type = "vinc16";
				compatible = "allwinner,sunxi-vin-core";
				reg = <0x0 0x05834000 0x0 0x1000>;
				interrupts = <GIC_SPI 145 IRQ_TYPE_LEVEL_HIGH>;
				vinc16_csi_sel = <2>;
				vinc16_mipi_sel = <0xff>;
				vinc16_isp_sel = <0>;
				vinc16_isp_tx_ch = <0>;
				vinc16_tdm_rx_sel = <0>;
				vinc16_rear_sensor_sel = <0>;
				vinc16_front_sensor_sel = <0>;
				vinc16_sensor_list = <0>;
				device_id = <16>;
				work_mode = <0x0>;
				iommus = <&mmu_aw 1 0>;
				status = "disabled";
			};

			vinc50:vinc@5835000 {
				device_type = "vinc17";
				compatible = "allwinner,sunxi-vin-core";
				reg = <0x0 0x05835000 0x0 0x1000>;
				interrupts = <GIC_SPI 146 IRQ_TYPE_LEVEL_HIGH>;
				vinc17_csi_sel = <2>;
				vinc17_mipi_sel = <0xff>;
				vinc17_isp_sel = <0>;
				vinc17_isp_tx_ch = <0>;
				vinc17_tdm_rx_sel = <0>;
				vinc17_rear_sensor_sel = <0>;
				vinc17_front_sensor_sel = <0>;
				vinc17_sensor_list = <0>;
				device_id = <17>;
				work_mode = <0x0>;
				iommus = <&mmu_aw 1 0>;
				status = "disabled";
			};
		};

	};
};
